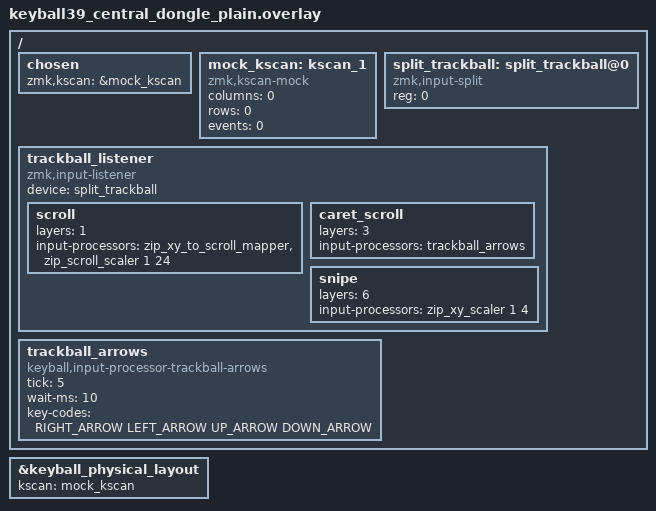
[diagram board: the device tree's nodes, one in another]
/*
 * Copyright (c) 2020 ZMK Contributors
 *
 * SPDX-License-Identifier: MIT
 */

#include "keyball39.dtsi"
#include <dt-bindings/zmk/keys.h>
#include <input/processors.dtsi>

/ {
    #address-cells = <1>;
    #size-cells = <0>;

    chosen {
        zmk,kscan = &mock_kscan;
        /delete-property/ zephyr,display;
    };

    mock_kscan: kscan_1 {
        compatible = "zmk,kscan-mock";
        columns = <0>;
        rows = <0>;
        events = <0>;
    };

    split_trackball: split_trackball@0 {
        compatible = "zmk,input-split";
        reg = <0>;
    };

    trackball_listener {
        compatible = "zmk,input-listener";
        device = <&split_trackball>;

        scroll {
            layers = <1>;
            input-processors =
                <&zip_xy_to_scroll_mapper>,
                <&zip_scroll_scaler 1 24>;
        };

        caret_scroll {
            layers = <3>;
            input-processors = <&trackball_arrows>;
        };

        snipe {
            layers = <6>;
            input-processors = <&zip_xy_scaler 1 4>;
        };
    };

    trackball_arrows: trackball_arrows {
        compatible = "keyball,input-processor-trackball-arrows";
        #input-processor-cells = <0>;
        tick = <5>;
        wait-ms = <10>;
        key-codes = <RIGHT_ARROW LEFT_ARROW UP_ARROW DOWN_ARROW>;
    };
};

&keyball_physical_layout {
    kscan = <&mock_kscan>;
};
